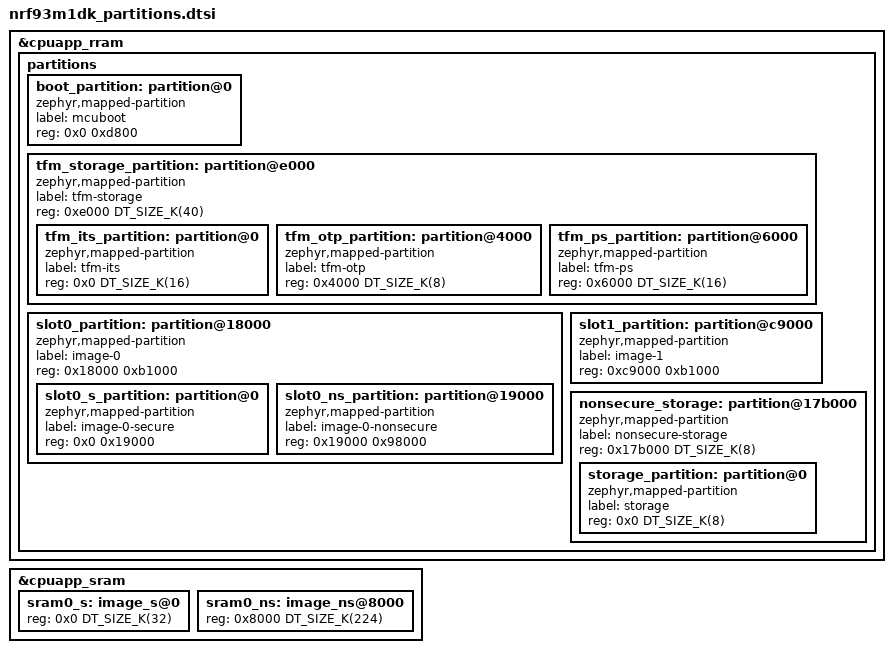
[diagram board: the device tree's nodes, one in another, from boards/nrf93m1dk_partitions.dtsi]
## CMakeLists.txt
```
#
# Copyright (c) 2026 Nordic Semiconductor ASA
#
# SPDX-License-Identifier: LicenseRef-Nordic-5-Clause
#

cmake_minimum_required(VERSION 3.20.0)

find_package(Zephyr REQUIRED HINTS $ENV{ZEPHYR_BASE})
project("Serial Modem Host - 93m1")

# Memfault CoAP includes unused nRF91 modem headers. Provide stubs on host MCU builds.
# Remove when Memfault updates their SDK
if(CONFIG_MEMFAULT_USE_NRF_CLOUD_COAP AND NOT CONFIG_NRF_MODEM_LIB)
	set(MEMFAULT_MODEM_SHIM ${CMAKE_CURRENT_SOURCE_DIR}/cmake/memfault-modem-shim)
	set(MEMFAULT_LIB_TARGET ..__modules__lib__memfault-firmware-sdk__ports__zephyr)
	if(TARGET ${MEMFAULT_LIB_TARGET})
		target_include_directories(${MEMFAULT_LIB_TARGET} BEFORE PRIVATE ${MEMFAULT_MODEM_SHIM})
	endif()
endif()

set(SMHA_LIB_DIR ${CMAKE_CURRENT_SOURCE_DIR}/../../lib)

zephyr_include_directories(
	${SMHA_LIB_DIR}/include
	${CMAKE_CURRENT_SOURCE_DIR}/src
)

target_sources(app PRIVATE
	src/main.c
	src/modules/network/network.c
)

target_sources_ifdef(CONFIG_SHELL app PRIVATE src/modules/network/network_shell.c)
target_sources_ifdef(CONFIG_APP_MEMFAULT app PRIVATE src/modules/memfault/memfault.c)
target_sources_ifdef(CONFIG_APP_BATTERY app PRIVATE src/modules/battery/battery.c)
target_sources_ifdef(CONFIG_APP_MODEM_AT app PRIVATE src/modules/modem_at/modem_at.c)
target_sources_ifdef(CONFIG_APP_MODEM_AT_SHELL app PRIVATE src/modules/modem_at/modem_at_shell.c)
target_sources_ifdef(CONFIG_APP_LOCATION app PRIVATE src/modules/location/location.c)
target_sources_ifdef(CONFIG_APP_LOCATION_SHELL app PRIVATE src/modules/location/location_shell.c)
target_sources_ifdef(CONFIG_APP_FOTA app PRIVATE src/modules/fota/fota.c)
target_sources_ifdef(CONFIG_APP_FOTA_SHELL app PRIVATE src/modules/fota/fota_shell.c)

# Memfault SDK guards new features with the minimum NCS version 3.4.0, which is yet to be released.
# Remove when the sdk tags 3.4.0.
if(CONFIG_APP_BATTERY AND CONFIG_MEMFAULT_NRF_PLATFORM_BATTERY_NPM13XX
   AND "${NCS_VERSION_MAJOR}.${NCS_VERSION_MINOR}.${NCS_VERSION_PATCH}" VERSION_LESS 3.4.0)
	zephyr_ld_options(-Wl,--wrap=nrf_fuel_gauge_init)
endif()
```

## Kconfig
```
#
# Copyright (c) 2026 Nordic Semiconductor ASA
#
# SPDX-License-Identifier: LicenseRef-Nordic-5-Clause
#

menu "Serial Modem Host 93m1"

rsource "src/Kconfig.main"
rsource "src/modules/network/Kconfig.network"
rsource "src/modules/memfault/Kconfig.memfault"
rsource "src/modules/fota/Kconfig.fota"
rsource "src/modules/battery/Kconfig.battery"
rsource "src/modules/modem_at/Kconfig.modem_at"
rsource "src/modules/location/Kconfig.location"

endmenu

menu "Zephyr Kernel"
source "Kconfig.zephyr"
endmenu
```

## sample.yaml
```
sample:
  name: Serial Modem Host 93m1
  description: Host application for nRF93M1 Smart Modem.
tests:
  serial_modem_host.applications.93m1:
    build_only: true
    integration_platforms:
      - nrf54l15dk/nrf54l15/cpuapp
    platform_allow:
      - nrf54l15dk/nrf54l15/cpuapp
    tags:
      - ci_build
```

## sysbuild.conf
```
#
# Copyright (c) 2026 Nordic Semiconductor ASA
#
# SPDX-License-Identifier: LicenseRef-Nordic-5-Clause
#

# Disable Partition Manager.
SB_CONFIG_PARTITION_MANAGER=n

# Enable MCUboot bootloader support.
SB_CONFIG_BOOTLOADER_MCUBOOT=y

# Add a merged hex file to the build output.
SB_CONFIG_MERGED_HEX_FILES=y
```

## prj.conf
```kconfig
#
# Copyright (c) 2026 Nordic Semiconductor ASA
#
# SPDX-License-Identifier: LicenseRef-Nordic-5-Clause
#

# Application identity
CONFIG_NCS_APPLICATION_BOOT_BANNER_STRING="Serial Modem Host 93m1"
CONFIG_MEMFAULT_NCS_FW_TYPE="smha-93m1"
CONFIG_MEMFAULT_NCS_FW_VERSION="1.0.0"
CONFIG_MEMFAULT_NCS_FW_VERSION_STATIC=y

# Application modules
CONFIG_APP_NETWORK=y
CONFIG_APP_NETWORK_SEARCH_NETWORK_ON_STARTUP=y
CONFIG_APP_MEMFAULT=y
CONFIG_APP_MODEM_AT=y
CONFIG_APP_LOCATION=y
CONFIG_APP_FOTA=y
CONFIG_APP_MODEM_AT_LOG_LEVEL_INF=y
CONFIG_APP_LOCATION_LOG_LEVEL_INF=y
CONFIG_APP_FOTA_LOG_LEVEL_INF=y
CONFIG_APP_BATTERY_LOG_LEVEL_INF=y

# System / RTOS
CONFIG_NCS_SAMPLES_DEFAULTS=y
CONFIG_RESET_ON_FATAL_ERROR=n
CONFIG_REBOOT=y
CONFIG_MAIN_STACK_SIZE=4096
# System heap: measured peak 3232 Bytes
CONFIG_HEAP_MEM_POOL_SIZE=8192
CONFIG_SYSTEM_WORKQUEUE_STACK_SIZE=4096
CONFIG_CBPRINTF_FP_SUPPORT=y
CONFIG_ZBUS=y
CONFIG_ZBUS_MSG_SUBSCRIBER=y
# SMF
CONFIG_SMF=y
CONFIG_SMF_ANCESTOR_SUPPORT=y
CONFIG_SMF_INITIAL_TRANSITION=y
CONFIG_TASK_WDT=y
CONFIG_SETTINGS=y
CONFIG_SETTINGS_NVS=y
CONFIG_NVS=y
CONFIG_HW_ID_LIBRARY=y
CONFIG_HW_ID_LIBRARY_SOURCE_DEVICE_ID=y
CONFIG_POSIX_API=y
CONFIG_POSIX_FILE_SYSTEM=n

# TF-M
CONFIG_TFM_CRYPTO_CONC_OPER_NUM=4
CONFIG_TFM_PARTITION_PROTECTED_STORAGE=y

# Logging
CONFIG_LOG=y
CONFIG_LOG_MODE_DEFERRED=y
CONFIG_LOG_BUFFER_SIZE=4096
CONFIG_NET_LOG=y
CONFIG_MODEM_CMUX_LOG_LEVEL_INF=y
CONFIG_MODEM_MODULES_LOG_LEVEL_INF=y

# Shell
CONFIG_SHELL=y
CONFIG_SHELL_STACK_SIZE=4096
CONFIG_SHELL_WILDCARD=n
CONFIG_SHELL_BACKEND_SERIAL_ASYNC_RX_BUFFER_SIZE=64
CONFIG_NET_SHELL=y

# Networking: PPP + IPv4/UDP only (no TCP; everything is CoAP/DTLS)
CONFIG_NETWORKING=y
CONFIG_NET_NATIVE=y
CONFIG_NET_L2_PPP=y
CONFIG_NET_L2_ETHERNET=n
CONFIG_NET_IPV4=y
CONFIG_NET_IPV6=n
CONFIG_NET_UDP=y
CONFIG_NET_TCP=n
CONFIG_NET_SOCKETS=y
CONFIG_NET_CONTEXT_RCVTIMEO=y
CONFIG_NET_MAX_CONN=12
CONFIG_NET_MAX_CONTEXTS=12
CONFIG_ZVFS_POLL_MAX=20
CONFIG_ZVFS_OPEN_MAX=20
CONFIG_NET_PKT_RX_COUNT=24
CONFIG_NET_PKT_TX_COUNT=24
CONFIG_NET_BUF_RX_COUNT=32
CONFIG_NET_BUF_TX_COUNT=32
CONFIG_NET_BUF_DATA_SIZE=256
CONFIG_NET_MGMT=y
CONFIG_NET_MGMT_EVENT=y
CONFIG_NET_CONNECTION_MANAGER=y
CONFIG_NET_CONNECTION_MANAGER_MONITOR_STACK_SIZE=512
CONFIG_NET_MGMT_EVENT_STACK_SIZE=800

# DNS
CONFIG_DNS_RESOLVER=y
CONFIG_NET_SOCKETS_DNS_TIMEOUT=10000
CONFIG_DNS_RESOLVER_AI_MAX_ENTRIES=8
CONFIG_DNS_NUM_CONCUR_QUERIES=4
CONFIG_DNS_RESOLVER_MAX_SERVERS=4
CONFIG_DNS_SERVER_IP_ADDRESSES=y
CONFIG_DNS_SERVER1="8.8.8.8"
CONFIG_DNS_SERVER2="1.1.1.1"
CONFIG_NET_L2_PPP_OPTION_DNS_USE=y

# Cellular modem
CONFIG_MODEM=y
CONFIG_MODEM_CELLULAR=y
CONFIG_MODEM_DEDICATED_WORKQUEUE=y
CONFIG_PM_DEVICE=y
CONFIG_PM_DEVICE_RUNTIME=y
CONFIG_PM_DEVICE_RUNTIME_USE_DEDICATED_WQ=y
CONFIG_MODEM_CMUX_MTU=127
CONFIG_MODEM_CMUX_WORK_BUFFER_SIZE_EXTRA=532
CONFIG_MODEM_CELLULAR_UART_BUFFER_SIZES=532
# App owns the user AT pipe (DLCI 3) via APP_MODEM_AT; stock AT shell off.
CONFIG_MODEM_AT_SHELL=n
CONFIG_MODEM_AT_USER_PIPE_IDX=0
CONFIG_MODEM_CELLULAR_USER_PIPE_BUFFER_SIZES=1024

# Board peripherals
CONFIG_GPIO=y
CONFIG_I2C=y
CONFIG_INPUT=y

# Battery: nPM13xx fuel gauge + charger
CONFIG_SENSOR=y
CONFIG_MFD=y
CONFIG_NPM13XX_CHARGER=y
CONFIG_NRF_FUEL_GAUGE=y
CONFIG_NRF_FUEL_GAUGE_VARIANT_SECONDARY_CELL=y
CONFIG_MEMFAULT_NRF_PLATFORM_BATTERY_NPM13XX=y
CONFIG_MEMFAULT_BATTERY_METRICS_BOOT_ON_SYSTEM_INIT=y

# Time: NTP over PPP
CONFIG_DATE_TIME=y
CONFIG_DATE_TIME_NTP=y
CONFIG_DATE_TIME_RETRY_COUNT=3
CONFIG_DATE_TIME_THREAD_STACK_SIZE=2048

# TLS credentials
CONFIG_TLS_CREDENTIALS=y
CONFIG_TLS_CREDENTIALS_SHELL=y
CONFIG_TLS_CREDENTIALS_SHELL_CRED_BUF_SIZE=3072
CONFIG_TFM_PARTITION_PROTECTED_STORAGE=y
CONFIG_TLS_CREDENTIALS_BACKEND_PROTECTED_STORAGE=y
CONFIG_TLS_MAX_CREDENTIALS_NUMBER=8
CONFIG_BASE64=y

# nRF Cloud CoAP
CONFIG_NRF_CLOUD=y
CONFIG_NRF_CLOUD_COAP=y
CONFIG_NRF_CLOUD_SEC_TAG=16842753
CONFIG_NRF_CLOUD_JWT_SOURCE_CUSTOM=y
CONFIG_NRF_CLOUD_CLIENT_ID_SRC_HW_ID=y
CONFIG_COAP_CLIENT_BLOCK_SIZE=1024
CONFIG_COAP_CLIENT_THREAD_PRIORITY=0
CONFIG_COAP_CLIENT_MAX_PATH_LENGTH=400
CONFIG_COAP_EXTENDED_OPTIONS_LEN_VALUE=192
CONFIG_NRF_CLOUD_COAP_MAX_USER_OPTIONS=2
CONFIG_COAP_CLIENT_MAX_EXTRA_OPTIONS=3
CONFIG_COAP_CLIENT_STACK_SIZE=4096

# Software DTLS
CONFIG_NET_SOCKETS_SOCKOPT_TLS=y
CONFIG_NET_SOCKETS_ENABLE_DTLS=y
CONFIG_MBEDTLS_SSL_DTLS_CONNECTION_ID=y
CONFIG_MBEDTLS_SSL_MAX_FRAGMENT_LENGTH=y
CONFIG_NET_SOCKETS_TLS_SET_MAX_FRAGMENT_LENGTH=y
CONFIG_NET_SOCKETS_TLS_MAX_CONTEXTS=3
CONFIG_NET_SOCKETS_TLS_MAX_CREDENTIALS=4
CONFIG_MBEDTLS_SSL_SERVER_NAME_INDICATION=y
CONFIG_MBEDTLS_SSL_IN_CONTENT_LEN=4096
CONFIG_MBEDTLS_SSL_OUT_CONTENT_LEN=2048
CONFIG_MBEDTLS_PEM_PARSE_C=y
CONFIG_MBEDTLS_DECLARE_PRIVATE_IDENTIFIERS=y
CONFIG_MBEDTLS_RSA_C=y
CONFIG_MBEDTLS_ECP_C=y
CONFIG_MBEDTLS_ECDSA_C=y
CONFIG_PSA_WANT_ALG_ECDH=y
CONFIG_PSA_WANT_ALG_ECDSA=y
CONFIG_PSA_WANT_ECC_SECP_R1_256=y
CONFIG_PSA_WANT_ECC_SECP_R1_384=y
CONFIG_PSA_WANT_ALG_SHA_1=y
CONFIG_MBEDTLS=y
CONFIG_MBEDTLS_ENABLE_HEAP=y
CONFIG_MBEDTLS_HEAP_SIZE=28672

# Memfault Telemetry
CONFIG_MEMFAULT=y
CONFIG_MEMFAULT_SHELL=y
CONFIG_MEMFAULT_USE_NRF_CLOUD_COAP=y
CONFIG_MEMFAULT_HTTP_ENABLE=n
CONFIG_MEMFAULT_NCS_DEVICE_ID_HW_ID=y
CONFIG_APP_MEMFAULT_THREAD_STACK_SIZE=4096
CONFIG_MEMFAULT_METRICS_HEARTBEAT_INTERVAL_SECS=3600
CONFIG_MEMFAULT_PERIODIC_UPLOAD=y
CONFIG_MEMFAULT_PERIODIC_UPLOAD_USE_SYSTEM_WORKQUEUE=y
CONFIG_MEMFAULT_PERIODIC_UPLOAD_INTERVAL_SECS=3600
CONFIG_MEMFAULT_LOGGING_ENABLE=y
CONFIG_MEMFAULT_LOGGING_RAM_SIZE=1536
CONFIG_MEMFAULT_NCS_STACK_METRICS=y
CONFIG_MEMFAULT_HEAP_STATS=y
CONFIG_MEMFAULT_COREDUMP_COLLECT_BSS_REGIONS=y
CONFIG_MEMFAULT_RAM_BACKED_COREDUMP_SIZE=3072
CONFIG_MEMFAULT_LOG_LEVEL_INF=y
CONFIG_MEMFAULT_NCS_LOG_LEVEL_INF=y

# FOTA
CONFIG_MEMFAULT_ZEPHYR_FOTA_BACKEND_NRF_CLOUD_OVERRIDE=y
CONFIG_NRF_CLOUD_FOTA=n
CONFIG_NRF_CLOUD_FOTA_POLL=y
CONFIG_NRF_CLOUD_COAP_DOWNLOADS=y
CONFIG_DOWNLOADER=y
CONFIG_DOWNLOADER_TRANSPORT_COAP=y
CONFIG_DOWNLOADER_TRANSPORT_HTTP=n
CONFIG_DOWNLOADER_STACK_SIZE=4096
CONFIG_DOWNLOADER_MAX_FILENAME_SIZE=512
CONFIG_FOTA_DOWNLOAD=y
CONFIG_FOTA_DOWNLOAD_PROGRESS_EVT=y
CONFIG_FOTA_SOCKET_RETRIES=5
CONFIG_DFU_TARGET=y
CONFIG_DFU_TARGET_MCUBOOT=y
CONFIG_IMG_MANAGER=y
CONFIG_MCUBOOT_IMG_MANAGER=y
CONFIG_FLASH=y
CONFIG_FLASH_MAP=y
CONFIG_STREAM_FLASH=y
CONFIG_STREAM_FLASH_ERASE=y
CONFIG_MPU_ALLOW_FLASH_WRITE=y
CONFIG_APP_FOTA_THREAD_STACK_SIZE=4096
CONFIG_APP_FOTA_WATCHDOG_TIMEOUT_SECONDS=900
CONFIG_APP_FOTA_MSG_PROCESSING_TIMEOUT_SECONDS=870
CONFIG_FOTA_DOWNLOAD_LOG_LEVEL_INF=y
```

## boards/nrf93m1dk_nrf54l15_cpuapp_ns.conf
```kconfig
#
# Copyright (c) 2026 Nordic Semiconductor ASA
#
# SPDX-License-Identifier: LicenseRef-Nordic-5-Clause
#

CONFIG_UART_INTERRUPT_DRIVEN=n
CONFIG_UART_ASYNC_API=y
CONFIG_SHELL_BACKEND_SERIAL_API_ASYNC=y
CONFIG_MODEM_BACKEND_UART_ASYNC_HWFC=y
CONFIG_MODEM_BACKEND_UART_ASYNC_RECEIVE_IDLE_TIMEOUT_MS=1

CONFIG_MODEM_CMUX_MTU=127
CONFIG_MODEM_CMUX_WORK_BUFFER_SIZE_EXTRA=532
CONFIG_MODEM_CELLULAR_UART_BUFFER_SIZES=532
CONFIG_MODEM_CMUX_MSC_FC_THRESHOLD=32

CONFIG_TFM_SFN=y
CONFIG_TFM_IPC=n
CONFIG_TFM_PSA_FRAMEWORK_HAS_MM_IOVEC=y
CONFIG_TFM_ITS_ENCRYPTED=n

# External SPI NOR is a Puya P25Q64; read its SFDP at runtime (jedec-id is
# overridden and the Macronix SFDP table removed in the board overlay).
CONFIG_SPI_NOR_SFDP_RUNTIME=y
```

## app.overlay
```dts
/*
 * Copyright (c) 2026 Nordic Semiconductor ASA
 *
 * SPDX-License-Identifier: Apache-2.0
 */

/* Switch control have pull-down that defaults to bypass mode, so delete the control GPIO */
/delete-node/ &modem_uart_switch;

&modem {
	status = "okay";
};

&modem_dcdc {
	startup-delay-us = <500000>; /* wait for 500ms to stabilize dcdc supply */
};
```

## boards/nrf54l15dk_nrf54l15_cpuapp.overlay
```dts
/*
 * Copyright (c) 2026 Nordic Semiconductor ASA
 *
 * SPDX-License-Identifier: LicenseRef-Nordic-5-Clause
 *
 * Placeholder overlay for nRF93M1 host UART routing.
 * Update pin assignments when the nRF93M1 DK board target is available in NCS.
 */

/ {
	chosen {
		/* zephyr,modem-uart = &uart30; */
	};
};

/*
 * &uart30 {
 *	pinctrl-0 = <&uart30_default>;
 *	pinctrl-1 = <&uart30_sleep>;
 *	pinctrl-names = "default", "sleep";
 *	current-speed = <115200>;
 *	status = "okay";
 * };
 */
```

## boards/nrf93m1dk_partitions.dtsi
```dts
/*
 * Copyright (c) 2026 Nordic Semiconductor ASA
 *
 * SPDX-License-Identifier: LicenseRef-Nordic-5-Clause
 */

/* Drop the board-default (no-MCUboot) partition and SRAM nodes. */
/delete-node/ &slot0_partition;
/delete-node/ &slot0_ns_partition;
/delete-node/ &tfm_ps_partition;
/delete-node/ &tfm_its_partition;
/delete-node/ &tfm_otp_partition;
/delete-node/ &storage_partition;
/delete-node/ &sram0_s;
/delete-node/ &sram0_ns;

&cpuapp_rram {
	partitions {
		boot_partition: partition@0 {
			compatible = "zephyr,mapped-partition";
			label = "mcuboot";
			reg = <0x0 0xd800>;
		};

		tfm_storage_partition: partition@e000 {
			compatible = "zephyr,mapped-partition";
			label = "tfm-storage";
			reg = <0xe000 DT_SIZE_K(40)>;
			ranges = <0x0 0xe000 DT_SIZE_K(40)>;
			#address-cells = <1>;
			#size-cells = <1>;

			tfm_its_partition: partition@0 {
				compatible = "zephyr,mapped-partition";
				label = "tfm-its";
				reg = <0x0 DT_SIZE_K(16)>;
			};

			tfm_otp_partition: partition@4000 {
				compatible = "zephyr,mapped-partition";
				label = "tfm-otp";
				reg = <0x4000 DT_SIZE_K(8)>;
			};

			tfm_ps_partition: partition@6000 {
				compatible = "zephyr,mapped-partition";
				label = "tfm-ps";
				reg = <0x6000 DT_SIZE_K(16)>;
			};
		};

		slot0_partition: partition@18000 {
			compatible = "zephyr,mapped-partition";
			label = "image-0";
			reg = <0x18000 0xb1000>;
			ranges = <0x0 0x18000 0xb1000>;
			#address-cells = <1>;
			#size-cells = <1>;

			slot0_s_partition: partition@0 {
				compatible = "zephyr,mapped-partition";
				label = "image-0-secure";
				reg = <0x0 0x19000>;
			};

			slot0_ns_partition: partition@19000 {
				compatible = "zephyr,mapped-partition";
				label = "image-0-nonsecure";
				reg = <0x19000 0x98000>;
			};
		};

		slot1_partition: partition@c9000 {
			compatible = "zephyr,mapped-partition";
			label = "image-1";
			reg = <0xc9000 0xb1000>;
		};

		nonsecure_storage: partition@17b000 {
			compatible = "zephyr,mapped-partition";
			label = "nonsecure-storage";
			reg = <0x17b000 DT_SIZE_K(8)>;
			ranges = <0x0 0x17b000 DT_SIZE_K(8)>;
			#address-cells = <1>;
			#size-cells = <1>;

			storage_partition: partition@0 {
				compatible = "zephyr,mapped-partition";
				label = "storage";
				reg = <0x0 DT_SIZE_K(8)>;
			};
		};
	};
};

/* SRAM: 32 KB secure / 224 KB non-secure */
&cpuapp_sram {
	sram0_s: image_s@0 {
		#address-cells = <1>;
		#size-cells = <1>;
		reg = <0x0 DT_SIZE_K(32)>;
		ranges = <0x0 0x0 DT_SIZE_K(32)>;
	};

	sram0_ns: image_ns@8000 {
		#address-cells = <1>;
		#size-cells = <1>;
		reg = <0x8000 DT_SIZE_K(224)>;
		ranges = <0x0 0x8000 DT_SIZE_K(224)>;
	};
};
```

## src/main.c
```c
/*
 * Copyright (c) 2026 Nordic Semiconductor ASA
 *
 * SPDX-License-Identifier: LicenseRef-Nordic-5-Clause
 */

#include <zephyr/kernel.h>
#include <zephyr/logging/log.h>
#include <zephyr/logging/log_ctrl.h>
#include <zephyr/zbus/zbus.h>
#include <zephyr/task_wdt/task_wdt.h>
#include <zephyr/smf.h>
#include <zephyr/sys/reboot.h>

#include "app_common.h"
#include "modules/network/network.h"
#if defined(CONFIG_APP_FOTA)
#include "modules/fota/fota.h"
#define FOTA_CHANNEL(X) X(fota_chan, struct fota_msg)
#else
#define FOTA_CHANNEL(X)
#endif

LOG_MODULE_REGISTER(main, CONFIG_APP_MAIN_LOG_LEVEL);

BUILD_ASSERT(CONFIG_APP_MAIN_WATCHDOG_TIMEOUT_SECONDS >
	     CONFIG_APP_MAIN_MSG_PROCESSING_TIMEOUT_SECONDS,
	     "Watchdog timeout must be greater than maximum message processing time");

enum main_msg_type {
	MAIN_START,
};

struct main_msg {
	enum main_msg_type type;
};

ZBUS_CHAN_DEFINE(main_chan,
		 struct main_msg,
		 NULL,
		 NULL,
		 ZBUS_OBSERVERS_EMPTY,
		 ZBUS_MSG_INIT(0));

ZBUS_MSG_SUBSCRIBER_DEFINE(main_subscriber);

#define CHANNEL_LIST(X) \
	X(main_chan, struct main_msg) \
	X(network_chan, struct network_msg) \
	FOTA_CHANNEL(X)

#define MAX_MSG_SIZE MAX_MSG_SIZE_FROM_LIST(CHANNEL_LIST)

#define ADD_OBSERVERS(_chan, _type) ZBUS_CHAN_ADD_OBS(_chan, main_subscriber, 0);

CHANNEL_LIST(ADD_OBSERVERS)

enum main_app_state {
	STATE_INIT,
	STATE_RUNNING,
};

struct main_state {
	struct smf_ctx ctx;
	const struct zbus_channel *chan;
	uint8_t msg_buf[MAX_MSG_SIZE];
};

static const struct smf_state states[];

static enum smf_state_result init_run(void *obj)
{
	struct main_state *state_object = obj;

	if (state_object->chan != &main_chan) {
		return SMF_EVENT_HANDLED;
	}

	const struct main_msg *msg = (const struct main_msg *)state_object->msg_buf;

	if (msg->type == MAIN_START) {
		smf_set_state(SMF_CTX(state_object), &states[STATE_RUNNING]);
	}

	return SMF_EVENT_HANDLED;
}

static void running_entry(void *obj)
{
	ARG_UNUSED(obj);

	LOG_INF("Serial Modem Host 93m1 starting");
}

static enum smf_state_result running_run(void *obj)
{
	struct main_state *state_object = obj;

	if (state_object->chan == &network_chan) {
		const struct network_msg *msg =
			(const struct network_msg *)state_object->msg_buf;

		switch (msg->type) {
		case NETWORK_CONNECTED:
			LOG_INF("Network connected");
			break;
		case NETWORK_DISCONNECTED:
			LOG_INF("Network disconnected");
#if defined(CONFIG_APP_FOTA)
			{
				struct fota_msg fota_msg = { .type = FOTA_NETWORK_DISCONNECTED };

				(void)zbus_chan_pub(&fota_chan, &fota_msg, PUB_TIMEOUT);
			}
#endif /* CONFIG_APP_FOTA */
			break;
		default:
			break;
		}

		return SMF_EVENT_HANDLED;
	}

#if defined(CONFIG_APP_FOTA)
	if (state_object->chan == &fota_chan) {
		const struct fota_msg *msg = (const struct fota_msg *)state_object->msg_buf;

		switch (msg->type) {
		case FOTA_NETWORK_DISCONNECT_NEEDED: {
			/* Bring the link down; the resulting NETWORK_DISCONNECTED */
			struct network_msg net_msg = { .type = NETWORK_DISCONNECT };
			int err = zbus_chan_pub(&network_chan, &net_msg, PUB_TIMEOUT);

			if (err) {
				LOG_ERR("zbus_chan_pub network_chan, error: %d", err);
				SEND_FATAL_ERROR();
			}
			break;
		}
		case FOTA_SUCCESS:
			LOG_INF("FOTA successful, rebooting to apply the update");
			LOG_PANIC();
			sys_reboot(SYS_REBOOT_COLD);
			break;
		case FOTA_STARTING:
			LOG_INF("FOTA download starting");
			break;
		case FOTA_ABORTED:
			LOG_INF("No FOTA update available");
			break;
		default:
			break;
		}

		return SMF_EVENT_HANDLED;
	}
#endif /* CONFIG_APP_FOTA */

	return SMF_EVENT_HANDLED;
}

static const struct smf_state states[] = {
	[STATE_INIT] = SMF_CREATE_STATE(NULL, init_run, NULL, NULL, NULL),
	[STATE_RUNNING] = SMF_CREATE_STATE(running_entry, running_run, NULL, NULL, NULL),
};

static void main_wdt_callback(int channel_id, void *user_data)
{
	LOG_ERR("Main watchdog expired, channel: %d, thread: %s",
		channel_id, k_thread_name_get((k_tid_t)user_data));

	SEND_FATAL_ERROR_WATCHDOG_TIMEOUT();
}

int main(void)
{
	int err;
	int task_wdt_id;
	const uint32_t wdt_timeout_ms =
		(CONFIG_APP_MAIN_WATCHDOG_TIMEOUT_SECONDS * MSEC_PER_SEC);
	const uint32_t execution_time_ms =
		(CONFIG_APP_MAIN_MSG_PROCESSING_TIMEOUT_SECONDS * MSEC_PER_SEC);
	const k_timeout_t zbus_wait = K_MSEC(wdt_timeout_ms - execution_time_ms);
	static struct main_state main_state;
	struct main_msg start_msg = {
		.type = MAIN_START,
	};

	task_wdt_id = task_wdt_add(wdt_timeout_ms, main_wdt_callback, (void *)k_current_get());
	if (task_wdt_id < 0) {
		LOG_ERR("Failed to add task to watchdog: %d", task_wdt_id);
		SEND_FATAL_ERROR();
		return -EFAULT;
	}

	smf_set_initial(SMF_CTX(&main_state), &states[STATE_INIT]);

	err = zbus_chan_pub(&main_chan, &start_msg, PUB_TIMEOUT);
	if (err) {
		LOG_ERR("zbus_chan_pub, error: %d", err);
		SEND_FATAL_ERROR();
		return -EFAULT;
	}

	while (true) {
		err = task_wdt_feed(task_wdt_id);
		if (err) {
			LOG_ERR("task_wdt_feed, error: %d", err);
			SEND_FATAL_ERROR();
			return -EFAULT;
		}

		err = zbus_sub_wait_msg(&main_subscriber, &main_state.chan,
					main_state.msg_buf, zbus_wait);
		if (err == -ENOMSG) {
			continue;
		} else if (err) {
			LOG_ERR("zbus_sub_wait_msg, error: %d", err);
			SEND_FATAL_ERROR();
			return -EFAULT;
		}

		err = smf_run_state(SMF_CTX(&main_state));
		if (err) {
			LOG_ERR("smf_run_state(), error: %d", err);
			SEND_FATAL_ERROR();
			return -EFAULT;
		}
	}

	return 0;
}
```
